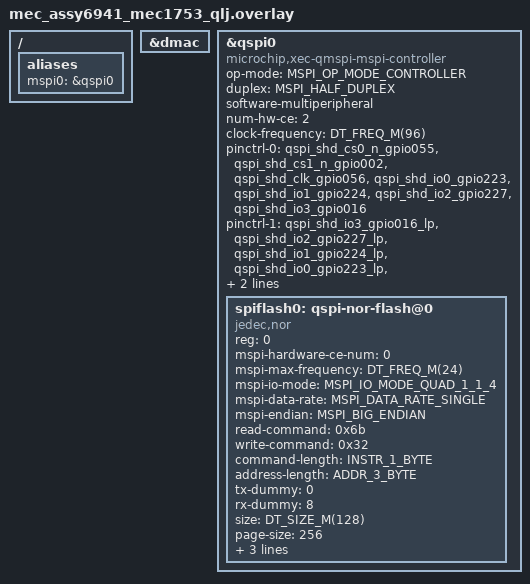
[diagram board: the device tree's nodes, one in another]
/*
 * Copyright (c) 2026 Microchip Technology Inc.
 *
 * SPDX-License-Identifier: Apache-2.0
 */

/ {
	aliases {
		mspi0 = &qspi0;
	};
};

&dmac {
	status = "okay";
};

&qspi0 {
	compatible = "microchip,xec-qmspi-mspi-controller";
	status = "okay";
	op-mode = "MSPI_OP_MODE_CONTROLLER";
	duplex = "MSPI_HALF_DUPLEX";
	software-multiperipheral; /* REQUIRED */
	num-hw-ce = <2>; /* Shared SPI supports two HW chip enables */
	clock-frequency = <DT_FREQ_M(96)>;

	pinctrl-0 = <&qspi_shd_cs0_n_gpio055 &qspi_shd_cs1_n_gpio002
		     &qspi_shd_clk_gpio056
		     &qspi_shd_io0_gpio223 &qspi_shd_io1_gpio224
		     &qspi_shd_io2_gpio227 &qspi_shd_io3_gpio016>;
	pinctrl-1 = <&qspi_shd_io3_gpio016_lp &qspi_shd_io2_gpio227_lp
		     &qspi_shd_io1_gpio224_lp &qspi_shd_io0_gpio223_lp
		     &qspi_shd_clk_gpio056_lp &qspi_shd_cs0_n_gpio055_fp>;
	pinctrl-names = "default", "sleep";

	/* Assembly-6791 SPI flash dongle conntected to EVB J18 2x10 with JP87 on 2-3 VTR1(3.3V)
	 * Dongle has four W25Q128JV 128 megabit 3.3 SPI flash chips
	 */
	spiflash0: qspi-nor-flash@0 {
		compatible = "jedec,nor";
		reg = <0>;

		mspi-hardware-ce-num = <0>;
		mspi-max-frequency = <DT_FREQ_M(24)>;
		mspi-io-mode = "MSPI_IO_MODE_QUAD_1_1_4";
		mspi-data-rate = "MSPI_DATA_RATE_SINGLE";
		mspi-endian = "MSPI_BIG_ENDIAN";
		read-command = <0x6b>;
		write-command = <0x32>;
		command-length = "INSTR_1_BYTE";
		address-length = "ADDR_3_BYTE";
		tx-dummy = <0>;
		rx-dummy = <8>;
		size = <DT_SIZE_M(128)>;
		page-size = <256>;
		quad-enable-requirements = "S2B1v4";
		jedec-id = [ef 40 18];
		sfdp-bfp = [00];
		status = "okay";
	};
};
